# APM32F107xx register map
File version: 1.0
CPU: CM3 r2p1, little endian, no MPU, no FPU, 4 interrupt priority bits
Registers are 32-bit, read-write, reset 0x0 unless marked. A register's access mark holds for its fields unless they carry their own. Offsets are from the block's base; [hi:lo] are bit positions.

## Ethernet_DMA — Ethernet: DMA controller operation
Base 0x40029000
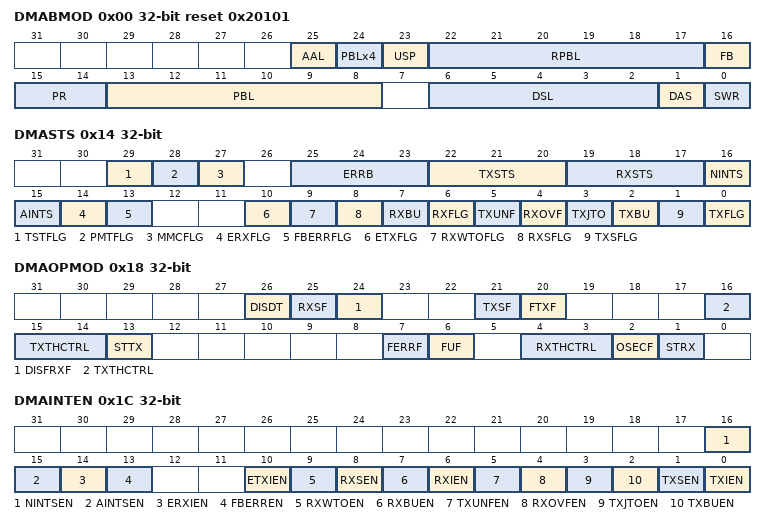
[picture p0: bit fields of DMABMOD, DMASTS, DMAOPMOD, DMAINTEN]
0x00 DMABMOD reset 0x20101 — Ethernet DMA bus mode register
  [25] AAL — Address-aligned beats
  [24] PBLx4 — 4xPBL mode
  [23] USP — Use separate PBL
  [22:17] RPBL — Rx DMA PBL
  [16] FB — Fixed burst
  [15:14] PR — Rx Tx priority ratio
  [13:8] PBL — Programmable burst length
  [6:2] DSL — Descriptor skip length
  [1] DAS — DMA Arbitration
  [0] SWR — Software reset
0x04 DMATXPD — Ethernet DMA transmit poll demand register
  [31:0] TXPD — Transmit poll demand
0x08 DMARXPD — EHERNET DMA receive poll demand register
  [31:0] RXPD — Receive poll demand
0x0C DMARXDLADDR — Ethernet DMA receive descriptor list address register
  [31:0] RXSTA — Start of receive list
0x10 DMATXDLADDR — Ethernet DMA transmit descriptor list address register
  [31:0] TXSTA — Start of transmit list
0x14 DMASTS access per field — Ethernet DMA status register
  [29] TSTFLG ro — Time stamp trigger status
  [28] PMTFLG ro — PMT status
  [27] MMCFLG ro — MMC status
  [25:23] ERRB ro — Error bits status
  [22:20] TXSTS ro — Transmit process state
  [19:17] RXSTS ro — Receive process state
  [16] NINTS rw — Normal interrupt summary
  [15] AINTS rw — Abnormal interrupt summary
  [14] ERXFLG rw — Early receive status
  [13] FBERRFLG rw — Fatal bus error status
  [10] ETXFLG rw — Early transmit status
  [9] RXWTOFLG rw — Receive watchdog timeout status
  [8] RXSFLG rw — Receive process stopped status
  [7] RXBU rw — Receive buffer unavailable status
  [6] RXFLG rw — Receive status
  [5] TXUNF rw — Transmit underflow status
  [4] RXOVF rw — Receive overflow status
  [3] TXJTO rw — Transmit jabber timeout status
  [2] TXBU rw — Transmit buffer unavailable status
  [1] TXSFLG rw — Transmit process stopped status
  [0] TXFLG rw — Transmit status
0x18 DMAOPMOD — Ethernet DMA operation mode register
  [26] DISDT — Disable Dropping of TCP/IP Checksum Error Frames
  [25] RXSF — Receive Store and Forward
  [24] DISFRXF — Disable Flushing of Received Frames
  [21] TXSF — Transmit Store and Forward
  [20] FTXF — Flush Transmit FIFO
  [16:14] TXTHCTRL — Transmit Threshold Control
  [13] STTX — Start or Stop Transmission Command
  [7] FERRF — Forward Error Frames
  [6] FUF — Forward Undersized Good Frames
  [4:3] RXTHCTRL — Receive Threshold Control
  [2] OSECF — Operate on Second Frame
  [1] STRX — Start or Stop Receive
0x1C DMAINTEN — Ethernet DMA interrupt enable register
  [16] NINTSEN — Normal interrupt summary enable
  [15] AINTSEN — Abnormal interrupt summary enable
  [14] ERXIEN — Early receive interrupt enable
  [13] FBERREN — Fatal bus error interrupt enable
  [10] ETXIEN — Early transmit interrupt enable
  [9] RXWTOEN — receive watchdog timeout interrupt enable
  [8] RXSEN — Receive process stopped interrupt enable
  [7] RXBUEN — Receive buffer unavailable interrupt enable
  [6] RXIEN — Receive interrupt enable
  [5] TXUNFEN — Underflow interrupt enable
  [4] RXOVFEN — Overflow interrupt enable
  [3] TXJTOEN — Transmit jabber timeout interrupt enable
  [2] TXBUEN — Transmit buffer unavailable interrupt enable
  [1] TXSEN — Transmit process stopped interrupt enable
  [0] TXIEN — Transmit interrupt enable
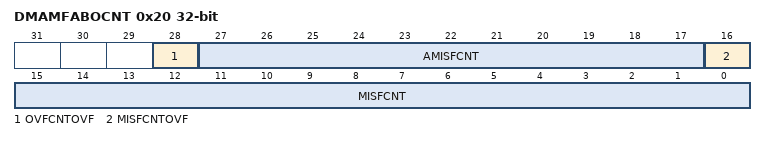
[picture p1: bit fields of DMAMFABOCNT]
0x20 DMAMFABOCNT ro — Ethernet DMA missed frame and buffer overflow counter register
  [28] OVFCNTOVF — Overflow bit for FIFO overflow counter
  [27:17] AMISFCNT — Missed frames by the application
  [16] MISFCNTOVF — Overflow bit for missed frame counter
  [15:0] MISFCNT — Missed frames by the controller
0x48 DMAHTXD ro — Ethernet DMA current host transmit descriptor register
  [31:0] HTXDADDRP — Host transmit descriptor address pointer
0x4C DMAHRXD ro — Ethernet DMA current host receive descriptor register
  [31:0] HRXDADDRP — Host receive descriptor address pointer
0x50 DMAHTXBADDR ro — Ethernet DMA current host transmit buffer address register
  [31:0] HTXBADDRP — Host transmit buffer address pointer
0x54 DMAHRXBADDR ro — Ethernet DMA current host receive buffer address register
  [31:0] HRXBADDRP — Host receive buffer address pointer
